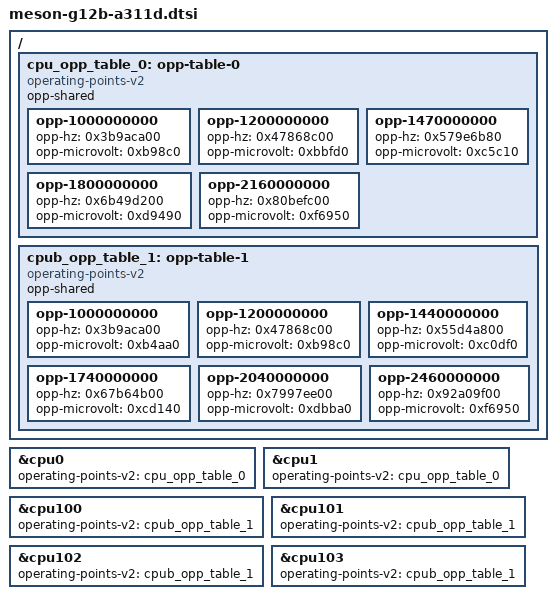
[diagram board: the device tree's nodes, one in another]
// SPDX-License-Identifier: (GPL-2.0+ OR MIT)
/*
 * Copyright (c) 2019 BayLibre, SAS
 * Author: Neil Armstrong <narmstrong@baylibre.com>
 */

#include "meson-g12b.dtsi"

/ {
	cpu_opp_table_0: opp-table-0 {
		compatible = "operating-points-v2";
		opp-shared;

		opp-1000000000 {
			opp-hz = /bits/ 64 <0x3b9aca00>;
			opp-microvolt = <0xb98c0>;
		};

		opp-1200000000 {
			opp-hz = /bits/ 64 <0x47868c00>;
			opp-microvolt = <0xbbfd0>;
		};

		opp-1470000000 {
			opp-hz = /bits/ 64 <0x579e6b80>;
			opp-microvolt = <0xc5c10>;
		};

		opp-1800000000 {
			opp-hz = /bits/ 64 <0x6b49d200>;
			opp-microvolt = <0xd9490>;
		};

		opp-2160000000 {
			opp-hz = /bits/ 64 <0x80befc00>;
			opp-microvolt = <0xf6950>;
		};
	};

	cpub_opp_table_1: opp-table-1 {
		compatible = "operating-points-v2";
		opp-shared;

		opp-1000000000 {
			opp-hz = /bits/ 64 <0x3b9aca00>;
			opp-microvolt = <0xb4aa0>;
		};

		opp-1200000000 {
			opp-hz = /bits/ 64 <0x47868c00>;
			opp-microvolt = <0xb98c0>;
		};

		opp-1440000000 {
			opp-hz = /bits/ 64 <0x55d4a800>;
			opp-microvolt = <0xc0df0>;
		};

		opp-1740000000 {
			opp-hz = /bits/ 64 <0x67b64b00>;
			opp-microvolt = <0xcd140>;
		};

		opp-2040000000 {
			opp-hz = /bits/ 64 <0x7997ee00>;
			opp-microvolt = <0xdbba0>;
		};

		opp-2460000000 {
			opp-hz = /bits/ 64 <0x92a09f00>;
			opp-microvolt = <0xf6950>;
		};
	};
};

&cpu0 {
	operating-points-v2 = <&cpu_opp_table_0>;
};

&cpu1 {
	operating-points-v2 = <&cpu_opp_table_0>;
};

&cpu100 {
	operating-points-v2 = <&cpub_opp_table_1>;
};

&cpu101 {
	operating-points-v2 = <&cpub_opp_table_1>;
};

&cpu102 {
	operating-points-v2 = <&cpub_opp_table_1>;
};

&cpu103 {
	operating-points-v2 = <&cpub_opp_table_1>;
};
